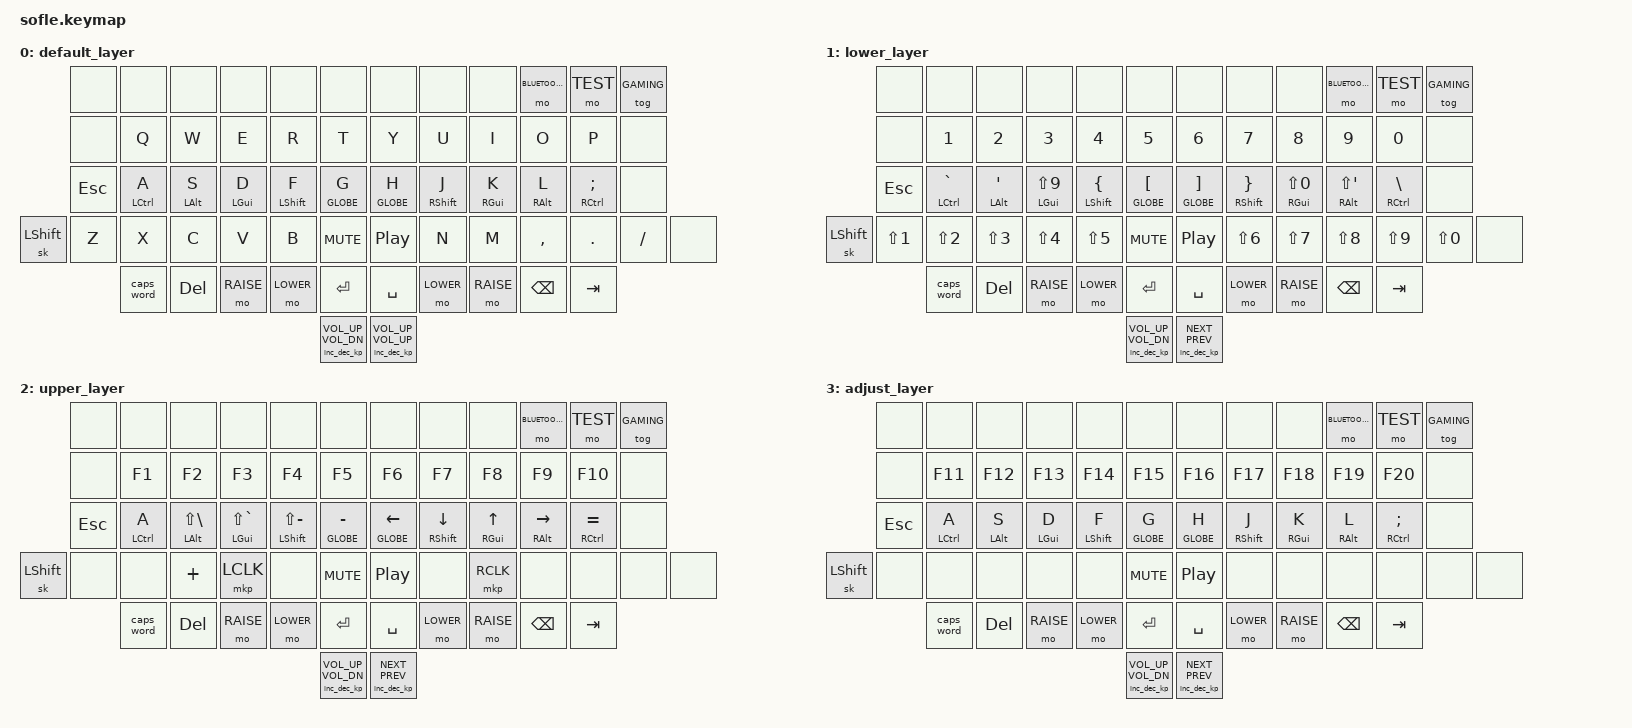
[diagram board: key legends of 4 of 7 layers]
/*
 * Copyright (c) 2020 The ZMK Contributors
 *
 * SPDX-License-Identifier: MIT
 */

#include <behaviors.dtsi>
#include <dt-bindings/zmk/keys.h>
#include <dt-bindings/zmk/bt.h>
#include <dt-bindings/zmk/mouse.h>



#define HOST_OS 2
#include "../zmk-nodefree-config/helper.h"

#include "../zmk-nodefree-config/keypos_def/keypos_60keys.h"

// Left keys without thumb or encoder keys
#define KEYS_L  LN5 LN4 LN3 LN2 LN1 LN0 LT5 LT4 LT3 LT2 LT1 LT0 LM5 LM4 LM3 LM2 LM1 LM0 LB5 LB4 LB3 LB2 LB1 LB0 

// Right keys without thumb or encoder keys
#define KEYS_R  RN0 RN1 RN2 RN3 RN4 RN5 RT0 RT1 RT2 RT3 RT4 RT5 RM0 RM1 RM2 RM3 RM4 RM5 RB0 RB1 RB2 RB3 RB4 RB5 

// All thumb keys
#define THUMBS  LH4 LH3 LH2 LH1 LH0 RH0 RH1 RH2 RH3 RH4 

#define BASE 0
#define LOWER 1
#define RAISE 2
#define ADJUST 3
#define BLUETOOTH 4
#define TEST 5
#define GAMING 6


/* left-hand HRMs */
ZMK_BEHAVIOR(hml, hold_tap,
    flavor = "balanced";
    tapping-term-ms = <280>;
    quick-tap-ms = <175>;                // repeat on tap-into-hold
    require-prior-idle-ms = <150>;
    bindings = <&kp>, <&kp>;
    hold-trigger-key-positions = <KEYS_R THUMBS>;
    hold-trigger-on-release;             // delay positional check until key-release
)

/* right-hand HRMs */
ZMK_BEHAVIOR(hmr, hold_tap,
    flavor = "balanced";
    tapping-term-ms = <280>;
    quick-tap-ms = <175>;                // repeat on tap-into-hold
    require-prior-idle-ms = <150>;
    bindings = <&kp>, <&kp>;
    hold-trigger-key-positions = <KEYS_L THUMBS>;
    hold-trigger-on-release;             // delay positional check until key-release
)

&sk {
  quick-release;
};


ZMK_LAYER(default_layer,
  &none  &none  &none  &none  &none  &none  &none  &none  &none  &mo BLUETOOTH  &mo TEST  &tog GAMING
  &none  &kp Q  &kp W  &kp E  &kp R  &kp T  &kp Y  &kp U  &kp I  &kp O  &kp P  &none
  &kp ESC  &hml LCTRL A  &hml LALT S  &hml LGUI D  &hml LSHIFT F  &hml GLOBE G  &hmr GLOBE H  &hmr RSHIFT J  &hmr RGUI K  &hmr RALT L  &hmr RCTRL SEMI &none
  &sk LSHIFT  &kp Z  &kp X  &kp C  &kp V  &kp B  &kp C_MUTE  &kp C_PP  &kp N  &kp M  &kp COMMA  &kp DOT  &kp FSLH  &none
  &caps_word  &kp DEL  &mo RAISE  &mo LOWER  &kp RETURN &kp SPACE &mo LOWER  &mo RAISE  &kp BSPC  &kp TAB  ,
  &inc_dec_kp C_VOL_UP C_VOL_DN &inc_dec_kp C_VOL_UP C_VOL_UP
)

ZMK_LAYER(lower_layer,
  &none  &none  &none  &none  &none  &none  &none  &none  &none  &mo BLUETOOTH  &mo TEST  &tog GAMING
  &none  &kp N1  &kp N2  &kp N3  &kp N4  &kp N5  &kp N6  &kp N7  &kp N8  &kp N9  &kp N0  &none
  &kp ESC  &hml LCTRL GRAVE  &hml LALT SQT  &hml LGUI LS(N9)  &hml LSHIFT LBRC  &hml GLOBE LBKT  &hmr GLOBE RBKT  &hmr RSHIFT RBRC  &hmr RGUI LS(N0)  &hmr RALT LS(SQT)  &hmr RCTRL BSLH  &none
  &sk LSHIFT  &kp LS(N1) &kp LS(N2) &kp LS(N3) &kp LS(N4) &kp LS(N5) &kp C_MUTE  &kp C_PP  &kp LS(N6) &kp LS(N7) &kp LS(N8) &kp LS(N9) &kp LS(N0) &none
  &caps_word  &kp DEL  &mo RAISE  &mo LOWER  &kp RETURN &kp SPACE &mo LOWER  &mo RAISE  &kp BSPC  &kp TAB  ,
  &inc_dec_kp C_VOL_UP C_VOL_DN &inc_dec_kp C_NEXT C_PREV
)

ZMK_LAYER(upper_layer,
  &none  &none  &none  &none  &none  &none  &none  &none  &none  &mo BLUETOOTH  &mo TEST  &tog GAMING
  &none  &kp F1  &kp F2  &kp F3  &kp F4  &kp F5  &kp F6  &kp F7  &kp F8  &kp F9  &kp F10  &none
  &kp ESC  &hml LCTRL A  &hml LALT LS(BSLH)  &hml LGUI LS(GRAVE)  &hml LSHIFT LS(MINUS)  &hml GLOBE MINUS  &hmr GLOBE LEFT  &hmr RSHIFT DOWN  &hmr RGUI UP  &hmr RALT RIGHT  &hmr RCTRL EQUAL &none
  &sk LSHIFT  &none  &none  &kp PLUS  &mkp LCLK  &none  &kp C_MUTE  &kp C_PP  &none  &mkp RCLK  &none  &none  &none  &none  
  &caps_word  &kp DEL  &mo RAISE  &mo LOWER  &kp RETURN &kp SPACE &mo LOWER  &mo RAISE  &kp BSPC  &kp TAB  ,
  &inc_dec_kp C_VOL_UP C_VOL_DN &inc_dec_kp C_NEXT C_PREV
)

ZMK_LAYER(adjust_layer,
  &none  &none  &none  &none  &none  &none  &none  &none  &none  &mo BLUETOOTH  &mo TEST  &tog GAMING
  &none  &kp F11  &kp F12  &kp F13  &kp F14  &kp F15  &kp F16  &kp F17  &kp F18  &kp F19  &kp F20  &none
  &kp ESC  &hml LCTRL A  &hml LALT S  &hml LGUI D  &hml LSHIFT F  &hml GLOBE G  &hmr GLOBE H  &hmr RSHIFT J  &hmr RGUI K  &hmr RALT L  &hmr RCTRL SEMI &none
  &sk LSHIFT  &none  &none  &none  &none  &none  &kp C_MUTE  &kp C_PP   &none  &none  &none  &none  &none  &none
  &caps_word  &kp DEL  &mo RAISE  &mo LOWER  &kp RETURN &kp SPACE &mo LOWER  &mo RAISE  &kp BSPC  &kp TAB  ,
  &inc_dec_kp C_VOL_UP C_VOL_DN &inc_dec_kp C_NEXT C_PREV
)

ZMK_LAYER(bluetooth_layer,
    &none  &none  &none  &none  &none  &none  &none  &none  &none  &mo BLUETOOTH  &mo TEST  &tog GAMING
    &none  &none  &none  &none  &none  &none  &none  &none  &none  &none  &none  &none
    &none  &bt BT_CLR  &bt BT_CLR_ALL  &bt BT_NXT  &bt BT_PRV  &none  &none  &none  &none  &none  &none
    &none  &none  &none  &none  &none  &none  &none  &none  &none  &none  &none  &none  &none  &none
    &none  &none  &none  &none  &none  &none  &none  &none  &none  &none  &none  &none 
)

ZMK_LAYER(test_layer,
    &none  &none  &none  &none  &none  &none  &none  &none  &none  &mo BLUETOOTH  &mo TEST  &tog GAMING
    &none  &kp C_NEXT  &kp C_PREV

)

ZMK_LAYER(gaming_layer,
    &kp N1  &kp N2  &none  &none  &none  &none  &none  &none  &none  &mo BLUETOOTH  &mo TEST  &tog GAMING

)

ZMK_CONDITIONAL_LAYER(1 2, 3)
